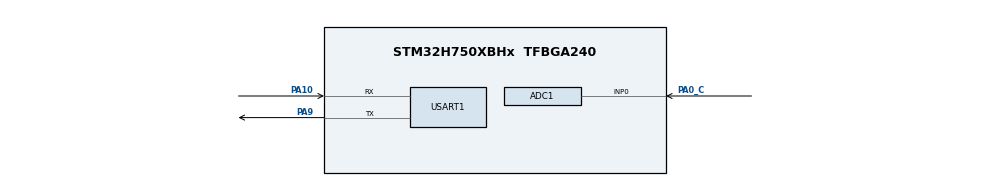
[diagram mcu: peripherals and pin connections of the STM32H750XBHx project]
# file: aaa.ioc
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ADC1.Channel-0\#ChannelRegularConversion=ADC_CHANNEL_0
ADC1.ClockPrescaler=ADC_CLOCK_ASYNC_DIV4
ADC1.ConversionDataManagement=ADC_CONVERSIONDATA_DMA_CIRCULAR
ADC1.ExternalTrigConv=ADC_EXTERNALTRIG_T3_TRGO
ADC1.NbrOfConversionFlag=1
ADC1.OffsetNumber-0\#ChannelRegularConversion=ADC_OFFSET_NONE
ADC1.OffsetSignedSaturation-0\#ChannelRegularConversion=DISABLE
ADC1.Overrun=ADC_OVR_DATA_OVERWRITTEN
ADC1.Rank-0\#ChannelRegularConversion=1
ADC1.Resolution=ADC_RESOLUTION_12B
ADC1.SamplingTime-0\#ChannelRegularConversion=ADC_SAMPLETIME_810CYCLES_5
ADC1.master=1
CORTEX_M7.default_mode_Activation=1
Dma.ADC1.0.Direction=DMA_PERIPH_TO_MEMORY
Dma.ADC1.0.EventEnable=DISABLE
Dma.ADC1.0.FIFOMode=DMA_FIFOMODE_DISABLE
Dma.ADC1.0.Instance=DMA1_Stream0
Dma.ADC1.0.MemDataAlignment=DMA_MDATAALIGN_HALFWORD
Dma.ADC1.0.MemInc=DMA_MINC_ENABLE
Dma.ADC1.0.Mode=DMA_CIRCULAR
Dma.ADC1.0.PeriphDataAlignment=DMA_PDATAALIGN_HALFWORD
Dma.ADC1.0.PeriphInc=DMA_PINC_DISABLE
Dma.ADC1.0.Polarity=HAL_DMAMUX_REQ_GEN_RISING
Dma.ADC1.0.Priority=DMA_PRIORITY_LOW
Dma.ADC1.0.RequestNumber=1
Dma.ADC1.0.SignalID=NONE
Dma.ADC1.0.SyncEnable=DISABLE
Dma.ADC1.0.SyncPolarity=HAL_DMAMUX_SYNC_NO_EVENT
Dma.ADC1.0.SyncRequestNumber=1
Dma.ADC1.0.SyncSignalID=NONE
Dma.Request0=ADC1
Mcu.Family=STM32H7
Mcu.Name=STM32H750XBHx
Mcu.Package=TFBGA240
NVIC.DMA1_Stream0_IRQn=true\:0\:0\:false\:false\:true\:false\:true\:true
NVIC.PriorityGroup=NVIC_PRIORITYGROUP_4
PA0_C.Signal=ADCx_INP0
PA10.Mode=Asynchronous
PA10.Signal=USART1_RX
PA9.Mode=Asynchronous
PA9.Signal=USART1_TX
PH0-OSC_IN\ (PH0).Mode=HSE-External-Oscillator
PH0-OSC_IN\ (PH0).Signal=RCC_OSC_IN
PH1-OSC_OUT\ (PH1).Mode=HSE-External-Oscillator
PH1-OSC_OUT\ (PH1).Signal=RCC_OSC_OUT
ProjectManager.HeapSize=0x200
ProjectManager.StackSize=0x400
ProjectManager.TargetToolchain=MDK-ARM V5.32
RCC.ADCFreq_Value=32000000
RCC.APB1Freq_Value=120000000
RCC.APB2Freq_Value=120000000
RCC.APB3Freq_Value=120000000
RCC.APB4Freq_Value=120000000
RCC.CortexFreq_Value=480000000
RCC.D1PPRE=RCC_APB3_DIV2
RCC.D2PPRE1=RCC_APB1_DIV2
RCC.D2PPRE2=RCC_APB2_DIV2
RCC.D3PPRE=RCC_APB4_DIV2
RCC.DIVM1=5
RCC.DIVM2=5
RCC.DIVN1=192
RCC.DIVN2=160
RCC.DIVP2=25
RCC.HCLKFreq_Value=240000000
RCC.HPRE=RCC_HCLK_DIV2
RCC.PLL2FRACN=0
RCC.PLL3FRACN=0
RCC.PLLFRACN=0
RCC.PLLSourceVirtual=RCC_PLLSOURCE_HSE
RCC.SYSCLKFreq_VALUE=480000000
RCC.SYSCLKSource=RCC_SYSCLKSOURCE_PLLCLK
RCC.USBFreq_Value=480000000
SH.ADCx_INP0.0=ADC1_INP0,IN0-Single-Ended
STMicroelectronics.X-CUBE-ALGOBUILD.1.4.0.LibraryCcDSPOoLibraryJjDSPOoLibrary=true
TIM3.AutoReloadPreload=TIM_AUTORELOAD_PRELOAD_ENABLE
TIM3.Period=999
TIM3.Prescaler=95
TIM3.TIM_MasterOutputTrigger=TIM_TRGO_UPDATE
USART1.VirtualMode-Asynchronous=VM_ASYNC
VP_STMicroelectronics.X-CUBE-ALGOBUILD_VS_DSPOoLibraryJjLibrary_1.4.0_1.4.0.Mode=DSPOoLibraryJjLibrary
VP_TIM3_VS_ClockSourceINT.Mode=Internal
board=custom

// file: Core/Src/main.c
/* USER CODE BEGIN Header */
/**
  ******************************************************************************
  * @file           : main.c
  * @brief          : Main program body
  ******************************************************************************
  * @attention
  *
  * Copyright (c) 2026 STMicroelectronics.
  * All rights reserved.
  *
  * This software is licensed under terms that can be found in the LICENSE file
  * in the root directory of this software component.
  * If no LICENSE file comes with this software, it is provided AS-IS.
  *
  ******************************************************************************
  */
/* USER CODE END Header */
#include "main.h"
#include "adc.h"
#include "dma.h"
#include "tim.h"
#include "usart.h"
#include "gpio.h"

/* USER CODE BEGIN Includes */
#include "stdio.h"
#include "arm_math.h"
/* USER CODE END Includes */

/* USER CODE BEGIN PD */
#define ADC_BUF_LEN     1024     // ADC采集点数（2秒数据@1kHz）
#define FFT_LENGTH      1024    // FFT点数（复数FFT）
#define SAMPLE_RATE     5000.0f // 采样率5kHz
/* USER CODE END PD */

/* USER CODE BEGIN PV */
uint16_t adc_buffer[ADC_BUF_LEN];
volatile uint8_t fft_done = 0;

// 复数FFT输入缓冲区（实部+虚部交错排列）
float fft_inputbuf[FFT_LENGTH * 2];
float fft_outputbuf[FFT_LENGTH];  // FFT幅度输出

// FFT实例（复数基4算法）
arm_cfft_radix4_instance_f32 scfft;
volatile uint8_t print_flag = 0;  // 标志

/* USER CODE END PV */

void SystemClock_Config(void);
static void MPU_Config(void);

/* USER CODE BEGIN 0 */
// printf重定向到串口
int fputc(int ch, FILE *f)
{
  HAL_UART_Transmit(&huart1, (uint8_t *)&ch, 1, 10);
  return ch;
}
/* USER CODE END 0 */

int main(void)
{

  /* MPU Configuration--------------------------------------------------------*/
  MPU_Config();

  /* MCU Configuration--------------------------------------------------------*/

  /* Reset of all peripherals, Initializes the Flash interface and the Systick. */
  HAL_Init();

  /* Configure the system clock */
  SystemClock_Config();

  /* Initialize all configured peripherals */
  MX_GPIO_Init();
  MX_DMA_Init();
  MX_ADC1_Init();
  MX_USART1_UART_Init();
  MX_TIM3_Init();
  /* USER CODE BEGIN 2 */
  // 初始化复数FFT（1024点基4算法）
  arm_cfft_radix4_init_f32(&scfft, FFT_LENGTH, 0, 1);

  // 校准并启动ADC DMA采集
  HAL_ADCEx_Calibration_Start(&hadc1, ADC_CALIB_OFFSET_LINEARITY, ADC_SINGLE_ENDED);
  HAL_ADC_Start_DMA(&hadc1, (uint32_t*)adc_buffer, ADC_BUF_LEN);
  HAL_TIM_Base_Start(&htim3);
  /* USER CODE END 2 */

  /* Infinite loop */
  /* USER CODE BEGIN WHILE */
  while (1)
  {
    if(fft_done)
    {
      fft_done = 0;
      HAL_ADC_Stop_DMA(&hadc1);

      // 1. 计算直流分量（去直流，消除0Hz峰值）
      float dc_offset = 0;
      for(int i = 0; i < FFT_LENGTH; i++) {
        dc_offset += adc_buffer[i];
      }
      dc_offset /= FFT_LENGTH;

      // 2. 准备复数FFT输入（实部=ADC值-直流，虚部=0）
      // 注意：只取前1024点ADC数据做FFT
      for(int i = 0; i < FFT_LENGTH; i++)
      {
        fft_inputbuf[2*i]   = (float)adc_buffer[i] - dc_offset;  // 实部
        fft_inputbuf[2*i+1] = 0.0f;                              // 虚部置0
      }

      // 3. 执行复数FFT（基4算法）
      arm_cfft_radix4_f32(&scfft, fft_inputbuf);

      // 4. 计算幅度谱（结果存到fft_outputbuf）
      // 注意：arm_cmplx_mag_f32计算的是模值 sqrt(实部²+虚部²)
      arm_cmplx_mag_f32(fft_inputbuf, fft_outputbuf, FFT_LENGTH);

      // 5. 串口输出FFT幅度谱（只输出前128点，0-128Hz，避免数据量过大）
      // 频率分辨率 = 1000Hz/1024 = 0.976Hz/点
      for(int i = 0; i < 128; i++)
      {
        printf("%.2f", fft_outputbuf[i]);
        if(i < 127) printf(",");
      }
      printf("\r\n");  // 换行标记一帧数据结束
      fflush(stdout);

      // 6. 重启DMA采集下一帧
      HAL_ADC_Start_DMA(&hadc1, (uint32_t*)adc_buffer, ADC_BUF_LEN);
    }
    HAL_Delay(1);
    /* USER CODE END WHILE */

  }
}

void SystemClock_Config(void)
{
  RCC_OscInitTypeDef RCC_OscInitStruct = {0};
  RCC_ClkInitTypeDef RCC_ClkInitStruct = {0};

  /** Supply configuration update enable
  */
  HAL_PWREx_ConfigSupply(PWR_LDO_SUPPLY);

  /** Configure the main internal regulator output voltage
  */
  __HAL_PWR_VOLTAGESCALING_CONFIG(PWR_REGULATOR_VOLTAGE_SCALE1);

  while(!__HAL_PWR_GET_FLAG(PWR_FLAG_VOSRDY)) {}

  __HAL_RCC_SYSCFG_CLK_ENABLE();
  __HAL_PWR_VOLTAGESCALING_CONFIG(PWR_REGULATOR_VOLTAGE_SCALE0);

  while(!__HAL_PWR_GET_FLAG(PWR_FLAG_VOSRDY)) {}

  /** Initializes the RCC Oscillators according to the specified parameters
  * in the RCC_OscInitTypeDef structure.
  */
  RCC_OscInitStruct.OscillatorType = RCC_OSCILLATORTYPE_HSE;
  RCC_OscInitStruct.HSEState = RCC_HSE_ON;
  RCC_OscInitStruct.PLL.PLLState = RCC_PLL_ON;
  RCC_OscInitStruct.PLL.PLLSource = RCC_PLLSOURCE_HSE;
  RCC_OscInitStruct.PLL.PLLM = 5;
  RCC_OscInitStruct.PLL.PLLN = 192;
  RCC_OscInitStruct.PLL.PLLP = 2;
  RCC_OscInitStruct.PLL.PLLQ = 2;
  RCC_OscInitStruct.PLL.PLLR = 2;
  RCC_OscInitStruct.PLL.PLLRGE = RCC_PLL1VCIRANGE_2;
  RCC_OscInitStruct.PLL.PLLVCOSEL = RCC_PLL1VCOWIDE;
  RCC_OscInitStruct.PLL.PLLFRACN = 0;
  if (HAL_RCC_OscConfig(&RCC_OscInitStruct) != HAL_OK)
  {
    Error_Handler();
  }

  /** Initializes the CPU, AHB and APB buses clocks
  */
  RCC_ClkInitStruct.ClockType = RCC_CLOCKTYPE_HCLK|RCC_CLOCKTYPE_SYSCLK
                              |RCC_CLOCKTYPE_PCLK1|RCC_CLOCKTYPE_PCLK2
                              |RCC_CLOCKTYPE_D3PCLK1|RCC_CLOCKTYPE_D1PCLK1;
  RCC_ClkInitStruct.SYSCLKSource = RCC_SYSCLKSOURCE_PLLCLK;
  RCC_ClkInitStruct.SYSCLKDivider = RCC_SYSCLK_DIV1;
  RCC_ClkInitStruct.AHBCLKDivider = RCC_HCLK_DIV2;
  RCC_ClkInitStruct.APB3CLKDivider = RCC_APB3_DIV2;
  RCC_ClkInitStruct.APB1CLKDivider = RCC_APB1_DIV2;
  RCC_ClkInitStruct.APB2CLKDivider = RCC_APB2_DIV2;
  RCC_ClkInitStruct.APB4CLKDivider = RCC_APB4_DIV2;

  if (HAL_RCC_ClockConfig(&RCC_ClkInitStruct, FLASH_LATENCY_4) != HAL_OK)
  {
    Error_Handler();
  }
}

/* USER CODE BEGIN 4 */

void HAL_ADC_ConvCpltCallback(ADC_HandleTypeDef* hadc)
{
    if(hadc->Instance == ADC1) fft_done = 1;
}

/* USER CODE END 4 */

 /* MPU Configuration */

void MPU_Config(void)
{
  MPU_Region_InitTypeDef MPU_InitStruct = {0};

  /* Disables the MPU */
  HAL_MPU_Disable();

  /** Initializes and configures the Region and the memory to be protected
  */
  MPU_InitStruct.Enable = MPU_REGION_ENABLE;
  MPU_InitStruct.Number = MPU_REGION_NUMBER0;
  MPU_InitStruct.BaseAddress = 0x0;
  MPU_InitStruct.Size = MPU_REGION_SIZE_4GB;
  MPU_InitStruct.SubRegionDisable = 0x87;
  MPU_InitStruct.TypeExtField = MPU_TEX_LEVEL0;
  MPU_InitStruct.AccessPermission = MPU_REGION_NO_ACCESS;
  MPU_InitStruct.DisableExec = MPU_INSTRUCTION_ACCESS_DISABLE;
  MPU_InitStruct.IsShareable = MPU_ACCESS_SHAREABLE;
  MPU_InitStruct.IsCacheable = MPU_ACCESS_NOT_CACHEABLE;
  MPU_InitStruct.IsBufferable = MPU_ACCESS_NOT_BUFFERABLE;

  HAL_MPU_ConfigRegion(&MPU_InitStruct);
  /* Enables the MPU */
  HAL_MPU_Enable(MPU_PRIVILEGED_DEFAULT);

}

void Error_Handler(void)
{
  __disable_irq();
  while (1)
  {
  }
}
